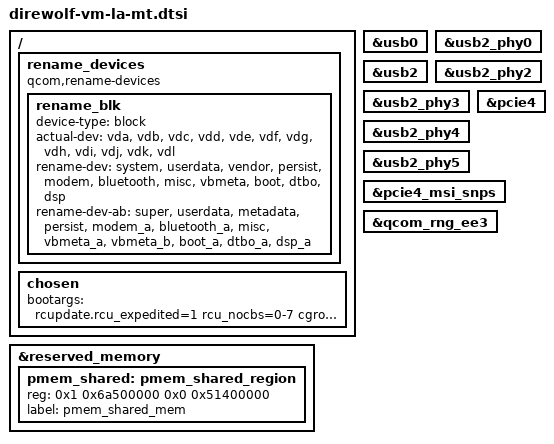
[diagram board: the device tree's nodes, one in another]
&reserved_memory {
	pmem_shared: pmem_shared_region {
		reg = <0x1 0x6a500000 0x0 0x51400000>;
		label = "pmem_shared_mem";
	};
};

#include "display/quin-vm-display-la.dtsi"
#include "direwolf-cnss.dtsi"

/ {
	rename_devices: rename_devices {
		compatible = "qcom,rename-devices";
		rename_blk: rename_blk {
			device-type = "block";
			actual-dev = "vda", "vdb", "vdc",
					"vdd", "vde", "vdf",
					"vdg", "vdh", "vdi",
					"vdj", "vdk", "vdl";
			rename-dev = "system", "userdata", "vendor",
					"persist", "modem", "bluetooth",
					"misc", "vbmeta", "boot", "dtbo",
					"dsp";
			rename-dev-ab = "super", "userdata", "metadata",
					"persist", "modem_a", "bluetooth_a",
					"misc", "vbmeta_a", "vbmeta_b",
					"boot_a", "dtbo_a", "dsp_a";
		};
	};

	chosen {
		bootargs = "rcupdate.rcu_expedited=1 rcu_nocbs=0-7 cgroup.memory=nokmem,nosocket androidboot.usbcontroller=a600000.dwc3 androidboot.fstab_suffix=gen4.qcom";
	};
};

&usb0 {
	status = "okay";
};

&usb2_phy0 {
	status = "okay";
};

&usb2 {
	status = "okay";
};

&usb2_phy2 {
	status = "okay";
};

&usb2_phy3 {
	status = "okay";
};

&usb2_phy4 {
	status = "okay";
};

&usb2_phy5 {
	status = "okay";
};

&pcie4 {
	status = "okay";
};

&pcie4_msi_snps {
	status = "okay";
};

&qcom_rng_ee3 {
	status = "okay";
};

#include "direwolf-vm-gnss.dtsi"
